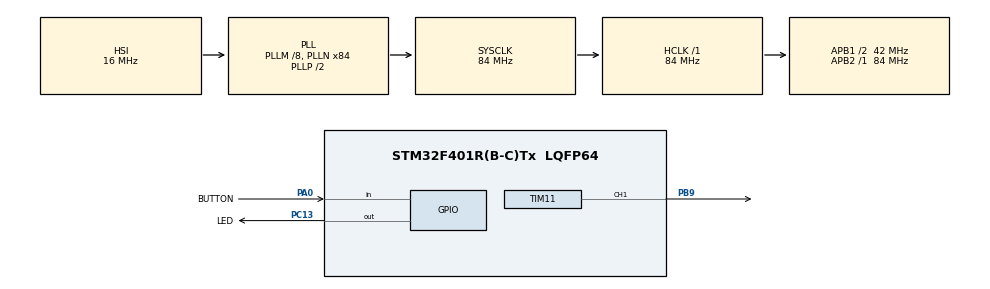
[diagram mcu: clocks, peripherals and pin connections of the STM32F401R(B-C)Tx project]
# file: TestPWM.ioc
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Mcu.Family=STM32F4
Mcu.Name=STM32F401R(B-C)Tx
Mcu.Package=LQFP64
NVIC.PriorityGroup=NVIC_PRIORITYGROUP_4
PA0-WKUP.GPIO_Label=BUTTON
PA0-WKUP.GPIO_PuPd=GPIO_PULLUP
PA0-WKUP.Signal=GPIO_Input
PB9.Signal=S_TIM11_CH1
PC13-ANTI_TAMP.GPIO_Label=LED
PC13-ANTI_TAMP.Signal=GPIO_Output
PC14-OSC32_IN.Mode=LSE-External-Oscillator
PC14-OSC32_IN.Signal=RCC_OSC32_IN
PC15-OSC32_OUT.Mode=LSE-External-Oscillator
PC15-OSC32_OUT.Signal=RCC_OSC32_OUT
PH0\ -\ OSC_IN.Mode=HSE-External-Oscillator
PH0\ -\ OSC_IN.Signal=RCC_OSC_IN
PH1\ -\ OSC_OUT.Mode=HSE-External-Oscillator
PH1\ -\ OSC_OUT.Signal=RCC_OSC_OUT
ProjectManager.HeapSize=0x200
ProjectManager.StackSize=0x400
ProjectManager.TargetToolchain=STM32CubeIDE
RCC.48MHZClocksFreq_Value=42000000
RCC.AHBFreq_Value=84000000
RCC.APB1CLKDivider=RCC_HCLK_DIV2
RCC.APB1Freq_Value=42000000
RCC.APB1TimFreq_Value=84000000
RCC.APB2Freq_Value=84000000
RCC.APB2TimFreq_Value=84000000
RCC.CortexFreq_Value=84000000
RCC.HCLKFreq_Value=84000000
RCC.HSE_VALUE=25000000
RCC.HSI_VALUE=16000000
RCC.PLLM=8
RCC.PLLN=84
RCC.SYSCLKFreq_VALUE=84000000
RCC.SYSCLKSource=RCC_SYSCLKSOURCE_PLLCLK
RCC.VCOOutputFreq_Value=168000000
SH.S_TIM11_CH1.0=TIM11_CH1,PWM Generation1 CH1
TIM11.Channel=TIM_CHANNEL_1
TIM11.Period=1023
VP_TIM11_VS_ClockSourceINT.Mode=Enable_Timer
board=custom

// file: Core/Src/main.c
/* USER CODE BEGIN Header */
/**
  ******************************************************************************
  * @file           : main.c
  * @brief          : Main program body
  ******************************************************************************
  * @attention
  *
  * Copyright (c) 2026 STMicroelectronics.
  * All rights reserved.
  *
  * This software is licensed under terms that can be found in the LICENSE file
  * in the root directory of this software component.
  * If no LICENSE file comes with this software, it is provided AS-IS.
  *
  ******************************************************************************
  */
/* USER CODE END Header */
#include "main.h"

/* USER CODE BEGIN Includes */
#include "Engine.h"
#include "SineTable.h"
/* USER CODE END Includes */

TIM_HandleTypeDef htim11;

/* USER CODE BEGIN PV */
float Saw[ 128 ] = { 0.0f, 0.015873f, 0.031746f, 0.047619f, 0.0634921f, 0.0793651f, 0.0952381f, 0.1111111f, 0.1269841f, 0.1428571f, 0.1587302f, 0.1746032f, 0.1904762f, 0.2063492f, 0.2222222f, 0.2380952f, 0.2539683f, 0.2698413f, 0.2857143f, 0.3015873f, 0.3174603f, 0.3333333f, 0.3492063f, 0.3650794f, 0.3809524f, 0.3968254f, 0.4126984f, 0.4285714f, 0.4444444f, 0.4603175f, 0.4761905f, 0.4920635f, 0.5079365f, 0.5238095f, 0.5396825f, 0.5555556f, 0.5714286f, 0.5873016f, 0.6031746f, 0.6190476f, 0.6349206f, 0.6507937f, 0.6666667f, 0.6825397f, 0.6984127f, 0.7142857f, 0.7301587f, 0.7460317f, 0.7619048f, 0.7777778f, 0.7936508f, 0.8095238f, 0.8253968f, 0.8412698f, 0.8571429f, 0.8730159f, 0.8888889f, 0.9047619f, 0.9206349f, 0.9365079f, 0.952381f, 0.968254f, 0.984127f, 1.0f, 0.9846154f, 0.9692308f, 0.9538462f, 0.9384615f, 0.9230769f, 0.9076923f, 0.8923077f, 0.8769231f, 0.8615385f, 0.8461538f, 0.8307692f, 0.8153846f, 0.8f, 0.7846154f, 0.7692308f, 0.7538462f, 0.7384615f, 0.7230769f, 0.7076923f, 0.6923077f, 0.6769231f, 0.6615385f, 0.6461538f, 0.6307692f, 0.6153846f, 0.6f, 0.5846154f, 0.5692308f, 0.5538462f, 0.5384615f, 0.5230769f, 0.5076923f, 0.4923077f, 0.4769231f, 0.4615385f, 0.4461538f, 0.4307692f, 0.4153846f, 0.4f, 0.3846154f, 0.3692308f, 0.3538462f, 0.3384615f, 0.3230769f, 0.3076923f, 0.2923077f, 0.2769231f, 0.2615385f, 0.2461538f, 0.2307692f, 0.2153846f, 0.2f, 0.1846154f, 0.1692308f, 0.1538462f, 0.1384615f, 0.1230769f, 0.1076923f, 0.0923077f, 0.0769231f, 0.0615385f, 0.0461538f, 0.0307692f, 0.0153846f };
float Sawtooth[ 128 ] = { 0.0f, 0.007874f, 0.015748f, 0.023622f, 0.0314961f, 0.0393701f, 0.0472441f, 0.0551181f, 0.0629921f, 0.0708661f, 0.0787402f, 0.0866142f, 0.0944882f, 0.1023622f, 0.1102362f, 0.1181102f, 0.1259843f, 0.1338583f, 0.1417323f, 0.1496063f, 0.1574803f, 0.1653543f, 0.1732283f, 0.1811024f, 0.1889764f, 0.1968504f, 0.2047244f, 0.2125984f, 0.2204724f, 0.2283465f, 0.2362205f, 0.2440945f, 0.2519685f, 0.2598425f, 0.2677165f, 0.2755906f, 0.2834646f, 0.2913386f, 0.2992126f, 0.3070866f, 0.3149606f, 0.3228346f, 0.3307087f, 0.3385827f, 0.3464567f, 0.3543307f, 0.3622047f, 0.3700787f, 0.3779528f, 0.3858268f, 0.3937008f, 0.4015748f, 0.4094488f, 0.4173228f, 0.4251969f, 0.4330709f, 0.4409449f, 0.4488189f, 0.4566929f, 0.4645669f, 0.4724409f, 0.480315f, 0.488189f, 0.496063f, 0.503937f, 0.511811f, 0.519685f, 0.5275591f, 0.5354331f, 0.5433071f, 0.5511811f, 0.5590551f, 0.5669291f, 0.5748031f, 0.5826772f, 0.5905512f, 0.5984252f, 0.6062992f, 0.6141732f, 0.6220472f, 0.6299213f, 0.6377953f, 0.6456693f, 0.6535433f, 0.6614173f, 0.6692913f, 0.6771654f, 0.6850394f, 0.6929134f, 0.7007874f, 0.7086614f, 0.7165354f, 0.7244094f, 0.7322835f, 0.7401575f, 0.7480315f, 0.7559055f, 0.7637795f, 0.7716535f, 0.7795276f, 0.7874016f, 0.7952756f, 0.8031496f, 0.8110236f, 0.8188976f, 0.8267717f, 0.8346457f, 0.8425197f, 0.8503937f, 0.8582677f, 0.8661417f, 0.8740157f, 0.8818898f, 0.8897638f, 0.8976378f, 0.9055118f, 0.9133858f, 0.9212598f, 0.9291339f, 0.9370079f, 0.9448819f, 0.9527559f, 0.9606299f, 0.9685039f, 0.976378f, 0.984252f, 0.992126f, 1.0f };

float Out;
float StateTime = 0.0f;
float NewTime = 0.0f;
volatile bool Step;
volatile uint32_t Overrun = 0;

Engine_TypeStateGeneratorADSR FastADSR;
Engine_TypeStateGeneratorADSR SlowADSR;

Engine_TypeStateGeneratorSaw SawC;
Engine_TypeStateGeneratorSaw SawG;
Engine_TypeStateGeneratorSaw SawC1;
Engine_TypeStateGeneratorSaw SawE;
Engine_TypeStateGeneratorSaw SawF;
Engine_TypeStateGeneratorSaw SawA;

Engine_TypeStateGeneratorSawtooth LeadC;
Engine_TypeStateGeneratorSawtooth LeadD;
Engine_TypeStateGeneratorSawtooth LeadE;
Engine_TypeStateGeneratorSawtooth LeadF;
Engine_TypeStateGeneratorSawtooth LeadG;

Engine_TypeStateGeneratorFastSine FastSine;

//Engine_TypeStateGeneratorSawtooth Sawtooth1;
/* USER CODE END PV */

void SystemClock_Config(void);
static void MX_GPIO_Init(void);
static void MX_TIM11_Init(void);

/* USER CODE BEGIN 0 */
/*void HAL_TIM_PeriodElapsedCallback( TIM_HandleTypeDef* htim )
{

	float Sum = Engine_GeneratorSineStep( &SineGenerator );

}*/
static uint32_t Normalized2PWM( float ValueNormalized )
{
	// da +- 1 a 0 - 1024
	return ( uint32_t )( ( ValueNormalized + 1.0f ) * 512.0f );
}

void TimerCallback( void )
{
	// leggi il file _it in fondo che spiega come collegare la callback anche se mx non la genera
	if( Step ){ Overrun++; }
	Step = true;
	TIM11->SR		&=	0xFFFFFFFE;	// reset interrupt*/
}
/* USER CODE END 0 */

int main(void)
{

  /* MCU Configuration--------------------------------------------------------*/

  /* Reset of all peripherals, Initializes the Flash interface and the Systick. */
  HAL_Init();

  /* USER CODE BEGIN Init */

	  StateTime = 0.0f;
	  NewTime = 0.0f;
	  Step = false;

	  Engine_GeneratorADSRInit( &SlowADSR, 1.0f, 1.0f, 0.75f, 3.0f, SAMPLERATE );
	  Engine_GeneratorADSRInit( &FastADSR, 0.1f, 1.0f, 0.5f, 0.3f, SAMPLERATE );

	  Engine_GeneratorSawInit( &SawC, Notes[ 0 ], 0.0f, SAMPLERATE );
	  Engine_GeneratorSawInit( &SawG, Notes[ 7 ], 0.2f, SAMPLERATE );
	  Engine_GeneratorSawInit( &SawC1, Notes[ 0 ] * 2.0f, 0.3f, SAMPLERATE );
	  Engine_GeneratorSawInit( &SawE, Notes[ 4 ], 0.1f, SAMPLERATE );
	  Engine_GeneratorSawInit( &SawF, Notes[ 5 ], 0.1f, SAMPLERATE );
	  Engine_GeneratorSawInit( &SawA, Notes[ 9 ], 0.1f, SAMPLERATE );

	  Engine_GeneratorSawtoothInit( &LeadC, Notes[ 0 ] * 2.0f, 0.1f, SAMPLERATE );
	  Engine_GeneratorSawtoothInit( &LeadD, Notes[ 2 ] * 2.0f, 0.3f, SAMPLERATE );
	  Engine_GeneratorSawtoothInit( &LeadE, Notes[ 4 ] * 2.0f, 0.15f, SAMPLERATE );
	  Engine_GeneratorSawtoothInit( &LeadF, Notes[ 5 ] * 2.0f, 0.2f, SAMPLERATE );
	  Engine_GeneratorSawtoothInit( &LeadG, Notes[ 7 ] * 2.0f, 0.3f, SAMPLERATE );

	  Engine_GeneratorFastSineInit( &FastSine, 20, 0.0f, SAMPLERATE );
  /* USER CODE END Init */

  /* Configure the system clock */
  SystemClock_Config();

  /* Initialize all configured peripherals */
  MX_GPIO_Init();
  MX_TIM11_Init();
  /* USER CODE BEGIN 2 */
  //TIM11->ARR 	= 	65535;
  //TIM11->CCR1 	= 	16384;
  // PER INIZIALIZZARE CORRETTAMENTE GUARDA IL REFERENCE MANUAL SOTTO LA SEZIONE PWM
  // TIENI APERTA UNA SCHEDA SULLA DESCRIZIONE CHE SPIEGA QUALI REGISTRI INIZIALIZZARE E IN QUALE ORDINE
  // NELL'ALTRA SCHEDA APRI I SINGOLI REGISTRI E CONFIGURA.
  // pg. 381 conteggio da 0 ad ARR quindi ARR + 1 impulsi.
  // pg. 415 condizioni di commutazione ccr = 0 -> pwm = 0 %, ccr = arr + 1 -> pwm = 100 %

  TIM11->ARR    = 	1023;       	// Periodo del PWM (Auto Reload Register)
  TIM11->CCR1   = 	0;           	// Duty cycle iniziale = 0%
  TIM11->CCMR1 	|= 	0x68;        	// CH1 in modalità PWM1 + preload CCR1
  TIM11->CR1   	|= 	0x80;        	// Abilita preload di ARR (ARPE)
  TIM11->EGR   	|= 	0x01;        	// Forza un evento di update per caricare i registri
  TIM11->CCER  	|= 	0x01;        	// Abilita l'uscita del canale 1
  TIM11->DIER  	|= 	0x01;        	// Abilita interrupt di Update (UIE)
  TIM11->SR    	&= 	0xFFFFFFFE;  	// Azzera il flag di Update (UIF)
  NVIC->ISER[0] |= 	0x04000000; 	// Abilita l'interrupt TIM1_TRG_COM_TIM11 nel NVIC
  TIM11->CR1   	|= 	0x01;        	// Avvia il timer (CEN)

  /* USER CODE END 2Engine_TypeStateGeneratorSaw SawC;
  Engine_TypeStateGeneratorSaw SawG;
  Engine_TypeStateGeneratorSaw SawC1;
  Engine_TypeStateGeneratorSaw SawE;
  Engine_TypeStateGeneratorSaw SawF;
  Engine_TypeStateGeneratorSaw SawA;
  Engine_TypeStateGeneratorSaw SawC; */

  /* Infinite loop */
  /* USER CODE BEGIN WHILE */

  while (1)
  {
	  if( Step )
	  {
		  Step = false;
		  Out = Engine_GeneratorFastSineStep( &FastSine );
		  //Out = Engine_GeneratorSineStep( &NormSine );
		  //Out = Engine_GeneratorSawStep(&SawC);
		  /*
		  NewTime = StateTime + ( 1.0f / SAMPLERATE );
		  Out = 0.0f;

		  // ACCORDI
		  if( NewTime >= 0.0f && NewTime < 8.0f * Fourth )
		  {
			  Out += Engine_GeneratorADSRStep( &SlowADSR, NewTime < ( 8.0f * Fourth ) - ( Fourth / 4.0f ) ) * (
					Engine_GeneratorSawStep( &SawC ) + Engine_GeneratorSawStep( &SawG ) + Engine_GeneratorSawStep( &SawC1 )
					) / 12.0f;
		  }
		  else if( NewTime >= 8.0f * Fourth && NewTime < 14.0f * Fourth )
		  {
			  Out += Engine_GeneratorADSRStep( &SlowADSR, NewTime < ( 14.0f * Fourth ) - ( Fourth / 4.0f ) ) * (
					  Engine_GeneratorSawStep( &SawC ) + Engine_GeneratorSawStep( &SawE ) + Engine_GeneratorSawStep( &SawG )
			  	  	  ) / 8.0f;
		  }
		  else if( NewTime >= 14.0f * Fourth && NewTime < 16.0f * Fourth )
		  {
			  Out += Engine_GeneratorADSRStep( &SlowADSR, NewTime < ( 16.0f * Fourth ) - ( Fourth / 2.0f ) ) * (
					  Engine_GeneratorSawStep( &SawC ) + Engine_GeneratorSawStep( &SawF ) + Engine_GeneratorSawStep( &SawA )
						) / 6.0f;
		  }

		  // LEAD
		  if( NewTime < 2.0f * Fourth )
		  {
			  Out += Engine_GeneratorADSRStep( &FastADSR, false ) * Engine_GeneratorSawtoothStep( &LeadC ) * 0.25f;
		  }
		  else if( NewTime >= 2.0f * Fourth && NewTime < 2.5f * Fourth  )
		  {
			  Out += Engine_GeneratorADSRStep( &FastADSR, true ) * Engine_GeneratorSawtoothStep( &LeadC ) * 0.25f;
		  }
		  else if( NewTime >= 2.5f * Fourth  && NewTime < 3.0f * Fourth )
		  {
			  Out += Engine_GeneratorADSRStep( &FastADSR, false ) * Engine_GeneratorSawtoothStep( &LeadC ) * 0.25f;
		  }
		  else if( NewTime >= 3.0f * Fourth && NewTime < 3.5f * Fourth )
		  {
			  Out += Engine_GeneratorADSRStep( &FastADSR, true ) * Engine_GeneratorSawtoothStep( &LeadC ) * 0.25f;
		  }
		  else if( NewTime >= 3.5f * Fourth && NewTime < 5.0f * Fourth )
		  {
			  Out += Engine_GeneratorADSRStep( &FastADSR, false ) * Engine_GeneratorSawtoothStep( &LeadC ) * 0.25f;
		  }
		  else if( NewTime >= 5.0f * Fourth && NewTime < 6.5f * Fourth )
		  {
			  Out += Engine_GeneratorADSRStep( &FastADSR, true ) * Engine_GeneratorSawtoothStep( &LeadG ) * 0.25f;
		  }
		  else if( NewTime >= 6.5f * Fourth && NewTime < 8.5f * Fourth )
		  {
			  Out += Engine_GeneratorADSRStep( &FastADSR, false ) * Engine_GeneratorSawtoothStep( &LeadG ) * 0.25f;
		  }
		  else if( NewTime >= 8.5f * Fourth && NewTime < 8.75f * Fourth )
		  {
			  Out += Engine_GeneratorADSRStep( &FastADSR, true ) * Engine_GeneratorSawtoothStep( &LeadC ) * 0.35f;
		  }
		  else if( NewTime >= 8.75f * Fourth && NewTime < 9.0f * Fourth )
		  {
			  Out += Engine_GeneratorADSRStep( &FastADSR, false ) * Engine_GeneratorSawtoothStep( &LeadC ) * 0.35f;
		  }
		  else if( NewTime >= 9.0f * Fourth && NewTime < 9.5f * Fourth )
		  {
			  Out += Engine_GeneratorADSRStep( &FastADSR, true ) * Engine_GeneratorSawtoothStep( &LeadC ) * 0.35f;
		  }
		  else if( NewTime >= 9.5f * Fourth && NewTime < 10.25f * Fourth )
		  {
			  Out += Engine_GeneratorADSRStep( &FastADSR, false ) * Engine_GeneratorSawtoothStep( &LeadC ) * 0.35f;
		  }
		  else if( NewTime >= 10.25f * Fourth && NewTime < 10.45f * Fourth )
		  {
			  Out += Engine_GeneratorADSRStep( &FastADSR, true ) * Engine_GeneratorSawtoothStep( &LeadC ) * 0.35f;
		  }
		  else if( NewTime >= 10.45f * Fourth && NewTime < 10.5 * Fourth )
		  {
			  Out += Engine_GeneratorADSRStep( &FastADSR, false ) * Engine_GeneratorSawtoothStep( &LeadC ) * 0.35f;
		  }
		  else if( NewTime >= 10.5f * Fourth && NewTime < 12.0f * Fourth )
		  {
			  Out += Engine_GeneratorADSRStep( &FastADSR, true ) * Engine_GeneratorSawtoothStep( &LeadG ) * 0.35f;
		  }
		  else if( NewTime >= 12.0f * Fourth && NewTime < 12.75f * Fourth )
		  {
			  Out += Engine_GeneratorADSRStep( &FastADSR, false ) * Engine_GeneratorSawtoothStep( &LeadG ) * 0.35f;
		  }
		  else if( NewTime >= 12.75f * Fourth && NewTime < 12.95f * Fourth )
		  {
			  Out += Engine_GeneratorADSRStep( &FastADSR, true ) * Engine_GeneratorSawtoothStep( &LeadC ) * 0.35f;
		  }
		  else if( NewTime >= 12.95f * Fourth && NewTime < 13.0f * Fourth )
		  {
			  Out += Engine_GeneratorADSRStep( &FastADSR, false ) * Engine_GeneratorSawtoothStep( &LeadC ) * 0.35f;
		  }
		  else if( NewTime >= 13.0f * Fourth && NewTime < 13.75f * Fourth )
		  {
			  Out += Engine_GeneratorADSRStep( &FastADSR, true ) * Engine_GeneratorSawtoothStep( &LeadE ) * 0.5f;
		  }
		  else if( NewTime >= 13.75f * Fourth && NewTime < 14.0f * Fourth )
		  {
			  Out += Engine_GeneratorADSRStep( &FastADSR, false ) * Engine_GeneratorSawtoothStep( &LeadE ) * 0.5f;
		  }
		  else if( NewTime >= 14.0f * Fourth && NewTime < 15.45f * Fourth )
		  {
			  Out += Engine_GeneratorADSRStep( &FastADSR, true ) * Engine_GeneratorSawtoothStep( &LeadD ) * 0.5f;
		  }
		  else if( NewTime >= 15.45f * Fourth && NewTime < 15.5f * Fourth )
		  {
			  Out += Engine_GeneratorADSRStep( &FastADSR, false ) * Engine_GeneratorSawtoothStep( &LeadD ) * 0.5f;
		  }
		  else if( NewTime >= 15.5f * Fourth && NewTime < 16.0f * Fourth )
		  {
			  Out += Engine_GeneratorADSRStep( &FastADSR, true ) * Engine_GeneratorSawtoothStep( &LeadC ) * 0.2f;
		  }

		  if( NewTime >= 16.0f * Fourth )
		  {
			  NewTime -= 16.0f * Fourth;
		  }
			*/
		  TIM11->CCR1 = Normalized2PWM( Out );

		  //StateTime = NewTime;
	  }
    /* USER CODE END WHILE */

  }
}

void SystemClock_Config(void)
{
  RCC_OscInitTypeDef RCC_OscInitStruct = {0};
  RCC_ClkInitTypeDef RCC_ClkInitStruct = {0};

  /** Configure the main internal regulator output voltage
  */
  __HAL_RCC_PWR_CLK_ENABLE();
  __HAL_PWR_VOLTAGESCALING_CONFIG(PWR_REGULATOR_VOLTAGE_SCALE2);

  /** Initializes the RCC Oscillators according to the specified parameters
  * in the RCC_OscInitTypeDef structure.
  */
  RCC_OscInitStruct.OscillatorType = RCC_OSCILLATORTYPE_HSI;
  RCC_OscInitStruct.HSIState = RCC_HSI_ON;
  RCC_OscInitStruct.HSICalibrationValue = RCC_HSICALIBRATION_DEFAULT;
  RCC_OscInitStruct.PLL.PLLState = RCC_PLL_ON;
  RCC_OscInitStruct.PLL.PLLSource = RCC_PLLSOURCE_HSI;
  RCC_OscInitStruct.PLL.PLLM = 8;
  RCC_OscInitStruct.PLL.PLLN = 84;
  RCC_OscInitStruct.PLL.PLLP = RCC_PLLP_DIV2;
  RCC_OscInitStruct.PLL.PLLQ = 4;
  if (HAL_RCC_OscConfig(&RCC_OscInitStruct) != HAL_OK)
  {
    Error_Handler();
  }

  /** Initializes the CPU, AHB and APB buses clocks
  */
  RCC_ClkInitStruct.ClockType = RCC_CLOCKTYPE_HCLK|RCC_CLOCKTYPE_SYSCLK
                              |RCC_CLOCKTYPE_PCLK1|RCC_CLOCKTYPE_PCLK2;
  RCC_ClkInitStruct.SYSCLKSource = RCC_SYSCLKSOURCE_PLLCLK;
  RCC_ClkInitStruct.AHBCLKDivider = RCC_SYSCLK_DIV1;
  RCC_ClkInitStruct.APB1CLKDivider = RCC_HCLK_DIV2;
  RCC_ClkInitStruct.APB2CLKDivider = RCC_HCLK_DIV1;

  if (HAL_RCC_ClockConfig(&RCC_ClkInitStruct, FLASH_LATENCY_2) != HAL_OK)
  {
    Error_Handler();
  }
}

static void MX_TIM11_Init(void)
{

  TIM_OC_InitTypeDef sConfigOC = {0};

  htim11.Instance = TIM11;
  htim11.Init.Prescaler = 0;
  htim11.Init.CounterMode = TIM_COUNTERMODE_UP;
  htim11.Init.Period = 1023;
  htim11.Init.ClockDivision = TIM_CLOCKDIVISION_DIV1;
  htim11.Init.AutoReloadPreload = TIM_AUTORELOAD_PRELOAD_DISABLE;
  if (HAL_TIM_Base_Init(&htim11) != HAL_OK)
  {
    Error_Handler();
  }
  if (HAL_TIM_PWM_Init(&htim11) != HAL_OK)
  {
    Error_Handler();
  }
  sConfigOC.OCMode = TIM_OCMODE_PWM1;
  sConfigOC.Pulse = 0;
  sConfigOC.OCPolarity = TIM_OCPOLARITY_HIGH;
  sConfigOC.OCFastMode = TIM_OCFAST_DISABLE;
  if (HAL_TIM_PWM_ConfigChannel(&htim11, &sConfigOC, TIM_CHANNEL_1) != HAL_OK)
  {
    Error_Handler();
  }
  HAL_TIM_MspPostInit(&htim11);

}

static void MX_GPIO_Init(void)
{
  GPIO_InitTypeDef GPIO_InitStruct = {0};

  /* GPIO Ports Clock Enable */
  __HAL_RCC_GPIOC_CLK_ENABLE();
  __HAL_RCC_GPIOH_CLK_ENABLE();
  __HAL_RCC_GPIOA_CLK_ENABLE();
  __HAL_RCC_GPIOB_CLK_ENABLE();

  /*Configure GPIO pin Output Level */
  HAL_GPIO_WritePin(LED_GPIO_Port, LED_Pin, GPIO_PIN_RESET);

  /*Configure GPIO pin : LED_Pin */
  GPIO_InitStruct.Pin = LED_Pin;
  GPIO_InitStruct.Mode = GPIO_MODE_OUTPUT_PP;
  GPIO_InitStruct.Pull = GPIO_NOPULL;
  GPIO_InitStruct.Speed = GPIO_SPEED_FREQ_LOW;
  HAL_GPIO_Init(LED_GPIO_Port, &GPIO_InitStruct);

  /*Configure GPIO pin : BUTTON_Pin */
  GPIO_InitStruct.Pin = BUTTON_Pin;
  GPIO_InitStruct.Mode = GPIO_MODE_INPUT;
  GPIO_InitStruct.Pull = GPIO_PULLUP;
  HAL_GPIO_Init(BUTTON_GPIO_Port, &GPIO_InitStruct);

}

void Error_Handler(void)
{
  __disable_irq();
  while (1)
  {
  }
}
